# GT32U2086 register map
Vendor: FPTTelecom
Registers are 32-bit, read-write, reset 0x0 unless marked. A register's access mark holds for its fields unless they carry their own. Offsets are from the block's base; [hi:lo] are bit positions; {n}, {i} and the like mark numbered series; 'fields as' and 'values as' point back to an identical list.

## DMA0 — DMA0 - GT32U2086 v8 FTEL DMA, 8 channels with 0x100-byte channel stride.
Base 0x44020000
Same registers: DMA1 0x50020000
{0x0+0x100*i} CH{i}_CMD_READ_ADDR (i=0..7) — Command source/read address
{0x4+0x100*i} CH{i}_CMD_WRITE_ADDR (i=0..7) — Command destination/write address
{0x8+0x100*i} CH{i}_CMD_TRANSFER_SIZE (i=0..7) — Command transfer size
  [9:0] SIZE — Transfer size
{0xC+0x100*i} CH{i}_CMD_CONTROL (i=0..7) — Command control word
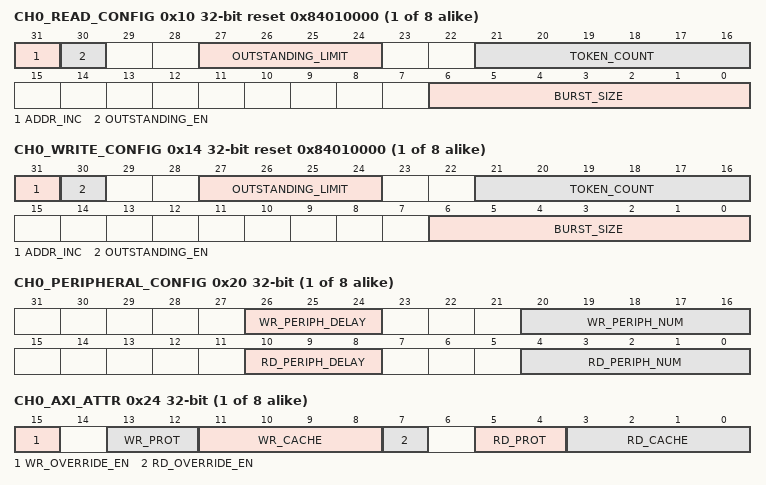
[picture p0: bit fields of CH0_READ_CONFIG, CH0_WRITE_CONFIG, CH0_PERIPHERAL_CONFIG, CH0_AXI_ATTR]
{0x10+0x100*i} CH{i}_READ_CONFIG reset 0x84010000 (i=0..7) — Read-side configuration
  [31] ADDR_INC — Increment address
  [30] OUTSTANDING_EN — Enable outstanding transactions
  [27:24] OUTSTANDING_LIMIT
  [21:16] TOKEN_COUNT
  [6:0] BURST_SIZE — Burst size in bytes
{0x14+0x100*i} CH{i}_WRITE_CONFIG reset 0x84010000 (i=0..7) — Write-side configuration
  fields as CH0_READ_CONFIG
{0x18+0x100*i} CH{i}_MODE_CONFIG (i=0..7) — Endianness mode
  [29:28] END_SWAP — Endianness swap mode
{0x1C+0x100*i} CH{i}_SCHEDULE_CONFIG (i=0..7) — Compatibility register; writes ignored by VP
{0x20+0x100*i} CH{i}_PERIPHERAL_CONFIG (i=0..7) — Peripheral request selection and delay
  [26:24] WR_PERIPH_DELAY — Write request delay
  [20:16] WR_PERIPH_NUM — Write peripheral ID
  [10:8] RD_PERIPH_DELAY — Read request delay
  [4:0] RD_PERIPH_NUM — Read peripheral ID
{0x24+0x100*i} CH{i}_AXI_ATTR (i=0..7) — Read/write bus attributes
  [15] WR_OVERRIDE_EN — Override write attributes
  [13:12] WR_PROT — Write protection attribute
  [11:8] WR_CACHE — Write cache attribute
  [7] RD_OVERRIDE_EN — Override read attributes
  [5:4] RD_PROT — Read protection attribute
  [3:0] RD_CACHE — Read cache attribute
{0x2C+0x100*i} CH{i}_RESTRICTION_STATUS ro (i=0..7) — Restriction status
{0x30+0x100*i} CH{i}_READ_OFFSET_STATUS ro (i=0..7) — Read offset status
{0x34+0x100*i} CH{i}_WRITE_OFFSET_STATUS ro (i=0..7) — Write offset status
{0x38+0x100*i} CH{i}_FIFO_STATUS ro (i=0..7) — FIFO free/used byte status
{0x3C+0x100*i} CH{i}_OUTSTANDING_STATUS ro (i=0..7) — Outstanding transaction status
{0x40+0x100*i} CH{i}_ENABLE reset 0x1 (i=0..7) — Channel enable
  [0] EN — Enable channel
{0x44+0x100*i} CH{i}_START wo (i=0..7) — Channel start pulse
  [0] START — Start pulse
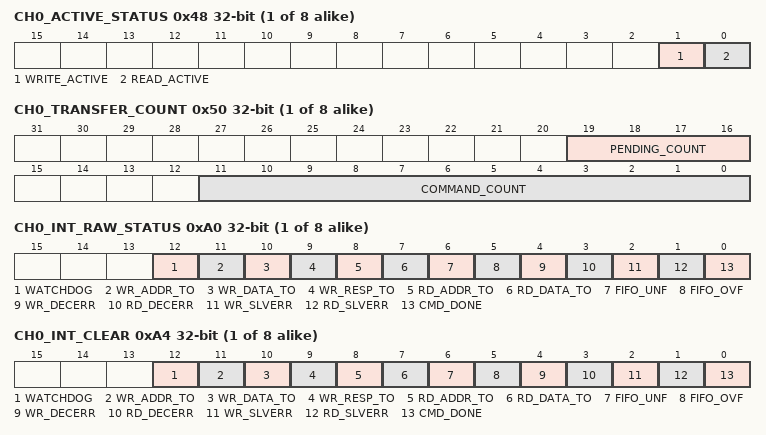
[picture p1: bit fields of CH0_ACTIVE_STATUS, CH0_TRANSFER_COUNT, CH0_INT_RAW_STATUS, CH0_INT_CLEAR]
{0x48+0x100*i} CH{i}_ACTIVE_STATUS ro (i=0..7) — Read/write active status
  [1] WRITE_ACTIVE — Write side active
  [0] READ_ACTIVE — Read side active
{0x50+0x100*i} CH{i}_TRANSFER_COUNT ro (i=0..7) — Completed command and pending-event counts
  [19:16] PENDING_COUNT — Pending events
  [11:0] COMMAND_COUNT — Completed commands
{0xA0+0x100*i} CH{i}_INT_RAW_STATUS (i=0..7) — Raw interrupt status
  [12] WATCHDOG — Watchdog event
  [11] WR_ADDR_TO — Write address timeout
  [10] WR_DATA_TO — Write data timeout
  [9] WR_RESP_TO — Write response timeout
  [8] RD_ADDR_TO — Read address timeout
  [7] RD_DATA_TO — Read data timeout
  [6] FIFO_UNF — FIFO underflow
  [5] FIFO_OVF — FIFO overflow
  [4] WR_DECERR — Write decode error
  [3] RD_DECERR — Read decode error
  [2] WR_SLVERR — Write slave error
  [1] RD_SLVERR — Read slave error
  [0] CMD_DONE — Command complete
{0xA4+0x100*i} CH{i}_INT_CLEAR wo (i=0..7) — Interrupt clear W1C
  fields as CH0_INT_RAW_STATUS
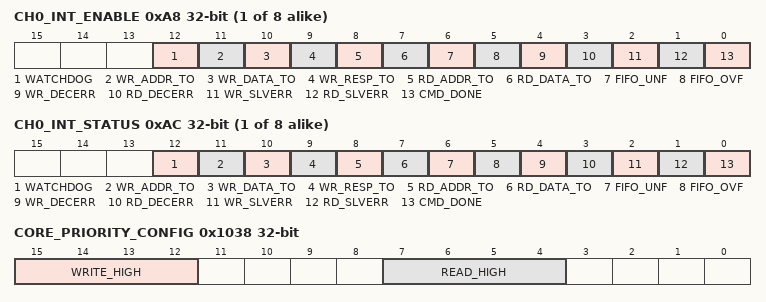
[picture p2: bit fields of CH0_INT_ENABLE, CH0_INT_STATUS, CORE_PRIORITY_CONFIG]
{0xA8+0x100*i} CH{i}_INT_ENABLE (i=0..7) — Interrupt enable
  fields as CH0_INT_RAW_STATUS
{0xAC+0x100*i} CH{i}_INT_STATUS ro (i=0..7) — Masked interrupt status
  fields as CH0_INT_RAW_STATUS
0x1000 CORE_STATUS ro — Core channel status
0x1030 CORE_JOINT_CONFIG — Compatibility register; reads zero
0x1038 CORE_PRIORITY_CONFIG — High-priority configuration
  [15:12] WRITE_HIGH — Write high priority
  [7:4] READ_HIGH — Read high priority
0x1040 CORE_CLOCK_DIVIDER — Compatibility register; reads zero
0x1048 CORE_CHANNEL_START wo — Start mask
  [7:0] CHANNELS — Channel start mask
0x1050 PERIPHERAL_RX_REQUEST — Peripheral RX request vector
  [31:1] REQUEST — Peripheral IDs 1..31
0x1054 PERIPHERAL_TX_REQUEST — Peripheral TX request vector
  [31:1] REQUEST — Peripheral IDs 1..31
0x10D0 CORE_IDLE_STATUS ro reset 0x1
  [0] IDLE — All channels idle
0x10E0 DESIGN_CAPABILITY ro reset 0x1
0x10F0 CORE_CAPABILITY0 ro reset 0xA602258
0x10F4 CORE_CAPABILITY1 ro reset 0xF1F
